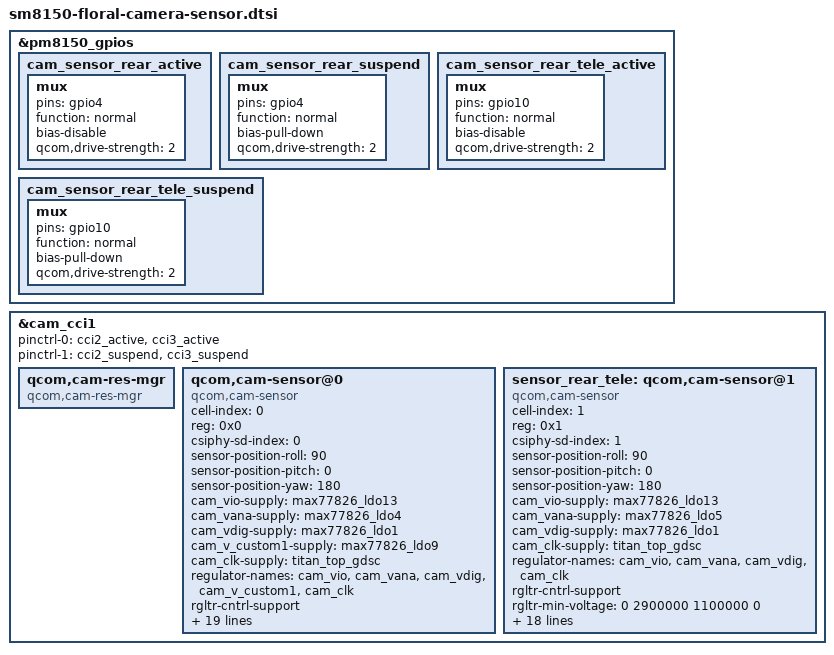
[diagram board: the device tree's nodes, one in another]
/*
* Copyright (c) 2018, The Linux Foundation. All rights reserved.
*
* This program is free software; you can redistribute it and/or modify
* it under the terms of the GNU General Public License version 2 and
* only version 2 as published by the Free Software Foundation.
*
* This program is distributed in the hope that it will be useful,
* but WITHOUT ANY WARRANTY; without even the implied warranty of
* MERCHANTABILITY or FITNESS FOR A PARTICULAR PURPOSE.  See the
* GNU General Public License for more details.
*/

&pm8150_gpios {
	cam_sensor_rear_active: cam_sensor_rear_active {
		mux {
			pins = "gpio4";
			function = "normal";
			bias-disable;
			qcom,drive-strength = <2>;
		};
	};

	cam_sensor_rear_suspend: cam_sensor_rear_suspend {
		mux {
			pins = "gpio4";
			function = "normal";
			bias-pull-down;
			qcom,drive-strength = <2>;
		};
	};

	cam_sensor_rear_tele_active: cam_sensor_rear_tele_active {
		mux {
			pins = "gpio10";
			function = "normal";
			bias-disable;
			qcom,drive-strength = <2>;
		};
	};

	cam_sensor_rear_tele_suspend: cam_sensor_rear_tele_suspend {
		mux {
			pins = "gpio10";
			function = "normal";
			bias-pull-down;
			qcom,drive-strength = <2>;
		};
	};
};

&cam_cci1 {
	pinctrl-0 = <&cci2_active &cci3_active>;
	pinctrl-1 = <&cci2_suspend &cci3_suspend>;

	qcom,cam-res-mgr {
		compatible = "qcom,cam-res-mgr";
		status = "ok";
	};

	qcom,cam-sensor@0 {
		cell-index = <0>;
		compatible = "qcom,cam-sensor";
		reg = <0x0>;
		csiphy-sd-index = <0>;
		sensor-position-roll = <90>;
		sensor-position-pitch = <0>;
		sensor-position-yaw = <180>;
		cam_vio-supply = <&max77826_ldo13>;
		cam_vana-supply = <&max77826_ldo4>;
		cam_vdig-supply = <&max77826_ldo1>;
		cam_v_custom1-supply = <&max77826_ldo9>;
		cam_clk-supply = <&titan_top_gdsc>;
		regulator-names = "cam_vio", "cam_vana", "cam_vdig",
			"cam_v_custom1", "cam_clk";
		rgltr-cntrl-support;
		rgltr-min-voltage = <0 2825000 1100000 1850000 0>;
		rgltr-max-voltage = <0 2825000 1100000 1850000 0>;
		rgltr-load-current = <0 80000 105000 80000 0>;
		gpio-no-mux = <0>;
		pinctrl-names = "cam_default", "cam_suspend";
		pinctrl-0 = <&cam_sensor_mclk2_active
			&cam_sensor_rear_active>;
		pinctrl-1 = <&cam_sensor_mclk2_suspend
			&cam_sensor_rear_suspend>;
		gpios = <&tlmm 15 0>,
			<&pm8150_gpios 4 0>;
		gpio-reset = <1>;
		gpio-req-tbl-num = <0 1>;
		gpio-req-tbl-flags = <1 0>;
		gpio-req-tbl-label = "CAMIF_MCLK0",
			"CAM_RESET0";
		sensor-mode = <0>;
		cci-device = <1>;
		cci-master = <0>;
		status = "ok";
		clocks = <&clock_camcc 76>;
		clock-names = "cam_clk";
		clock-cntl-level = "turbo";
		clock-rates = <24000000>;
	};

	sensor_rear_tele: qcom,cam-sensor@1 {
		cell-index = <1>;
		compatible = "qcom,cam-sensor";
		reg = <0x1>;
		csiphy-sd-index = <1>;
		sensor-position-roll = <90>;
		sensor-position-pitch = <0>;
		sensor-position-yaw = <180>;
		cam_vio-supply  = <&max77826_ldo13>;
		cam_vana-supply = <&max77826_ldo5>;
		cam_vdig-supply = <&max77826_ldo1>;
		cam_clk-supply  = <&titan_top_gdsc>;
		regulator-names = "cam_vio", "cam_vana", "cam_vdig",
			"cam_clk";
		rgltr-cntrl-support;
		rgltr-min-voltage  = <0 2900000 1100000 0>;
		rgltr-max-voltage  = <0 2900000 1100000 0>;
		rgltr-load-current = <0 80000 105000 0>;
		gpio-no-mux = <0>;
		pinctrl-names = "cam_default", "cam_suspend";
		pinctrl-0 = <&cam_sensor_mclk2_active
			&cam_sensor_rear_tele_active>;
		pinctrl-1 = <&cam_sensor_mclk2_suspend
			&cam_sensor_rear_tele_suspend>;
		gpios = <&tlmm 15 0>,
			<&pm8150_gpios 10 0>;
		gpio-reset = <1>;
		gpio-req-tbl-num = <0 1>;
		gpio-req-tbl-flags = <1 0>;
		gpio-req-tbl-label = "CAMIF_MCLK1",
			"CAM_RESET1";
		sensor-mode = <0>;
		cci-master = <1>;
		cci-device = <1>;
		status = "ok";
		clocks = <&clock_camcc 76>;
		clock-names = "cam_clk";
		clock-cntl-level = "turbo";
		clock-rates = <24000000>;
	};
};
